# STM32MP23_CM33 register map
File version: 1.2
CPU: CM33 r0p1, little endian, MPU, FPU, vendor SysTick, 8 interrupt priority bits
Registers are 32-bit, read-write, reset 0x0 unless marked. A register's access mark holds for its fields unless they carry their own. Offsets are from the block's base; [hi:lo] are bit positions; {n}, {i} and the like mark numbered series; 'fields as' and 'values as' point back to an identical list.

## TIM16 — General purpose timers
Base 0x40260000
Same registers: TIM17 0x40270000, TIM16_S 0x50260000, TIM17_S 0x50270000
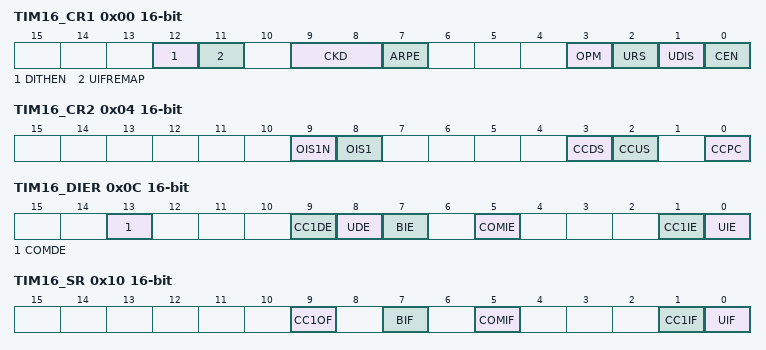
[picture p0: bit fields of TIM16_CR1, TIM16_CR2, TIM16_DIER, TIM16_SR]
0x00 TIM16_CR1 16-bit — TIM16 control register 1
  [12] DITHEN — Dithering enable Note: The DITHEN bit can only be modified when CEN bit is reset.
    0=Dithering disabled; 1=Dithering enabled
  [11] UIFREMAP — UIF status bit remapping
    0=No remapping. UIF status bit is not copied to TIMx_CNT register bit 31.; 1=Remapping enabled. UIF status bit is copied to TIMx_CNT register bit 31.
  [9:8] CKD — Clock division This bit-field indicates the division ratio between the timer clock (tim_ker_ck) frequency and the dead-time and sampling clock (tDTS)used by the dead-time generators and the digital filters (tim_tix),
    0=tDTS=ttim_ker_ck; 1=tDTS=2*ttim_ker_ck; 2=tDTS=4*ttim_ker_ck
  [7] ARPE — Auto-reload preload enable
    0=TIMx_ARR register is not buffered; 1=TIMx_ARR register is buffered
  [3] OPM — One pulse mode
    0=Counter is not stopped at update event; 1=Counter stops counting at the next update event (clearing the bit CEN)
  [2] URS — Update request source This bit is set and cleared by software to select the UEV event sources. Counter overflow/underflow Setting the UG bit Update generation through the slave mode controller
    0=Any of the following events generate an update interrupt or DMA request if enabled. These events can be:; 1=nly counter overflow/underflow generates an update interrupt or DMA request if enabled
  [1] UDIS — Update disable This bit is set and cleared by software to enable/disable UEV event generation. Counter overflow/underflow Setting the UG bit Update generation through the slave mode controller Buffered registers are then loaded with their preload values.
    0=UEV enabled. The Update (UEV) event is generated by one of the following events:; 1=UEV disabled. The Update event is not generated, shadow registers keep their value (ARR, PSC, CCRx). However the counter and the prescaler are reinitialized if the UG bit is set or if a hardware reset is received from the slave mode controller.
  [0] CEN — Counter enable Note: External clock and gated mode can work only if the CEN bit has been previously set by software. However trigger mode can set the CEN bit automatically by hardware.
    0=Counter disabled; 1=Counter enabled
0x04 TIM16_CR2 16-bit — TIM16 control register 2
  [9] OIS1N — Output Idle state 1 (tim_oc1n output) Note: This bit can not be modified as long as LOCK level 1, 2 or 3 has been programmed (LOCK bits in TIMx_BKR register).
    0=tim_oc1n=0 after a dead-time when MOE=0; 1=tim_oc1n=1 after a dead-time when MOE=0
  [8] OIS1 — Output Idle state 1 (tim_oc1 output) Note: This bit can not be modified as long as LOCK level 1, 2 or 3 has been programmed (LOCK bits in TIMx_BKR register).
    0=tim_oc1=0 after a dead-time when MOE=0; 1=tim_oc1=1 after a dead-time when MOE=0
  [3] CCDS — Capture/compare DMA selection
    0=CCx DMA request sent when CCx event occurs; 1=CCx DMA requests sent when update event occurs
  [2] CCUS — Capture/compare control update selection Note: This bit acts only on channels that have a complementary output.
    0=When capture/compare control bits are preloaded (CCPC=1), they are updated by setting the COMG bit only; 1=When capture/compare control bits are preloaded (CCPC=1), they are updated by setting the COMG bit or when a rising edge occurs on tim_trgi (if available)
  [0] CCPC — Capture/compare preloaded control Note: This bit acts only on channels that have a complementary output.
    0=CCxE, CCxNE and OCxM bits are not preloaded; 1=CCxE, CCxNE and OCxM bits are preloaded, after having been written, they are updated only when COM bit is set
0x0C TIM16_DIER 16-bit — TIM16 DMA/interrupt enable register
  [13] COMDE — COM DMA request enable
    0=COM DMA request disabled; 1=COM DMA request enabled
  [9] CC1DE — Capture/Compare 1 DMA request enable
    0=CC1 DMA request disabled; 1=CC1 DMA request enabled
  [8] UDE — Update DMA request enable
    0=Update DMA request disabled; 1=Update DMA request enabled
  [7] BIE — Break interrupt enable
    0=Break interrupt disabled; 1=Break interrupt enabled
  [5] COMIE — COM interrupt enable
    0=COM interrupt disabled; 1=COM interrupt enabled
  [1] CC1IE — Capture/Compare 1 interrupt enable
    0=CC1 interrupt disabled; 1=CC1 interrupt enabled
  [0] UIE — Update interrupt enable
    0=Update interrupt disabled; 1=Update interrupt enabled
0x10 TIM16_SR 16-bit — TIM16 status register
  [9] CC1OF — Capture/Compare 1 overcapture flag This flag is set by hardware only when the corresponding channel is configured in input capture mode. It is cleared by software by writing it to 0 .
    0=No overcapture has been detected; 1=The counter value has been captured in TIMx_CCR1 register while CC1IF flag was already set
  [7] BIF — Break interrupt flag This flag is set by hardware as soon as the tim_brk input goes active. It can be cleared by software if the break input is not active.
    0=No break event occurred; 1=An active level has been detected on the break input
  [5] COMIF — COM interrupt flag This flag is set by hardware on a COM event (once the capture/compare control bits CCxE, CCxNE, OCxM  have been updated). It is cleared by software.
    0=No COM event occurred; 1=COM interrupt pending
  [1] CC1IF — Capture/Compare 1 interrupt flag This flag is set by hardware. It is cleared by software (input capture or output compare mode) or by reading the TIMx_CCR1 register (input capture mode only). If channel CC1 is configured as output: this flag is set when the content of the counter TIMx_CNT matches the content of the TIMx_CCR1 register. When the content of TIMx_CCR1 is greater than the content of TIMx_ARR, the CC1IF bit goes high on the counter overflow (in up-counting and up/down-counting modes) or underflow (in down-counting mode). There are 3 possible options for flag setting in center-aligned mode, refer to the CMS bits in the TIMx_CR1 register for the full description. If channel CC1 is configured as input: this bit is set when counter value has been captured in TIMx_CCR1 register (an edge has been detected on IC1, as per the edge sensitivity defined with the CC1P and CC1NP bits setting, in TIMx_CCER).
    0=No compare match / No input capture occurred; 1=A compare match or an input capture occurred
  [0] UIF — Update interrupt flag This bit is set by hardware on an update event. It is cleared by software. At overflow regarding the repetition counter value (update if repetition counter = 0) and if the UDIS=0 in the TIMx_CR1 register. When CNT is reinitialized by software using the UG bit in TIMx_EGR register, if URS=0 and UDIS=0 in the TIMx_CR1 register.
    0=No update occurred; 1=Update interrupt pending. This bit is set by hardware when the registers are updated:
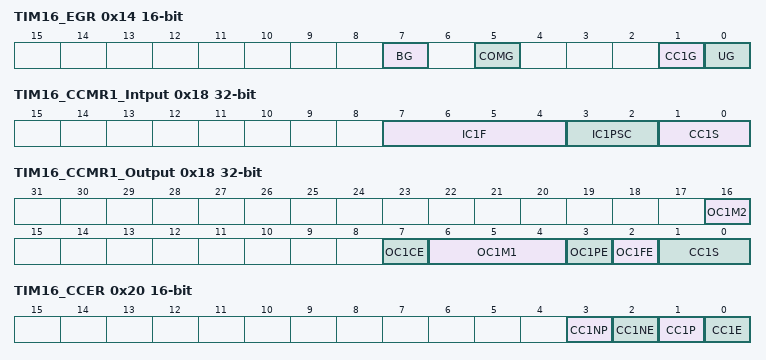
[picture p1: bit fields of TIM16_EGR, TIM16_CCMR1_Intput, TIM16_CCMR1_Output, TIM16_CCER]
0x14 TIM16_EGR 16-bit wo — TIM16 event generation register
  [7] BG — Break generation This bit is set by software in order to generate an event, it is automatically cleared by hardware.
    0=No action; 1=A break event is generated. MOE bit is cleared and BIF flag is set. Related interrupt or DMA transfer can occur if enabled.
  [5] COMG — Capture/Compare control update generation This bit can be set by software, it is automatically cleared by hardware. Note: This bit acts only on channels that have a complementary output.
    0=No action; 1=When the CCPC bit is set, it is possible to update the CCxE, CCxNE and OCxM bits
  [1] CC1G — Capture/Compare 1 generation This bit is set by software in order to generate an event, it is automatically cleared by hardware. If channel CC1 is configured as output: CC1IF flag is set, Corresponding interrupt or DMA request is sent if enabled. If channel CC1 is configured as input: The current value of the counter is captured in TIMx_CCR1 register. The CC1IF flag is set, the corresponding interrupt or DMA request is sent if enabled. The CC1OF flag is set if the CC1IF flag was already high.
    0=No action; 1=A capture/compare event is generated on channel 1:
  [0] UG — Update generation This bit can be set by software, it is automatically cleared by hardware.
    0=No action; 1=Reinitialize the counter and generates an update of the registers. Note that the prescaler counter is cleared too (anyway the prescaler ratio is not affected).
0x18 TIM16_CCMR1_Intput — TIM16 capture/compare mode register 1 [alternate]
  [7:4] IC1F — Input capture 1 filter This bit-field defines the frequency used to sample tim_ti1 input and the length of the digital filter applied to tim_ti1. The digital filter is made of an event counter in which N consecutive events are needed to validate a transition on the output:
    0=No filter, sampling is done at fDTS; 1=fSAMPLING=ftim_ker_ck, N=2; 2=fSAMPLING=ftim_ker_ck, N=4; 3=fSAMPLING=ftim_ker_ck, N=8; 4=fSAMPLING=fDTS/2, N=; 5=fSAMPLING=fDTS/2, N=8; 6=fSAMPLING=fDTS/4, N=6; 7=fSAMPLING=fDTS/4, N=8; 8=fSAMPLING=fDTS/8, N=6; 9=fSAMPLING=fDTS/8, N=8; 10=fSAMPLING=fDTS/16, N=5; 11=fSAMPLING=fDTS/16, N=6; 12=fSAMPLING=fDTS/16, N=8; 13=fSAMPLING=fDTS/32, N=5; 14=fSAMPLING=fDTS/32, N=6; 15=fSAMPLING=fDTS/32, N=8
  [3:2] IC1PSC — Input capture 1 prescaler This bit-field defines the ratio of the prescaler acting on CC1 input (tim_ic1). The prescaler is reset as soon as CC1E= 0 (TIMx_CCER register).
    0=no prescaler, capture is done each time an edge is detected on the capture input; 1=capture is done once every 2 events; 2=capture is done once every 4 events; 3=capture is done once every 8 events
  [1:0] CC1S — Capture/Compare 1 selection This bit-field defines the direction of the channel (input/output) as well as the used input. Others: Reserved Note: CC1S bits are writable only when the channel is OFF (CC1E = 0 in TIMx_CCER).
    0=CC1 channel is configured as output; 1=CC1 channel is configured as input, tim_ic1 is mapped on tim_ti1
0x18 TIM16_CCMR1_Output (alternate view of TIM16_CCMR1_Intput) — TIM16 capture/compare mode register 1 [alternate]
  [16] OC1M2 — Output Compare 1 mode These bits define the behavior of the output reference signal tim_oc1ref from which tim_oc1 and tim_oc1n are derived. tim_oc1ref is active high whereas tim_oc1 and tim_oc1n active level depends on CC1P and CC1NP bits. Others: Reserved Note: These bits can not be modified as long as LOCK level 3 has been programmed (LOCK bits in TIMx_BDTR register) and CC1S= 00 (the channel is configured in output). In PWM mode 1 or 2, the tim_oc1ref level changes only when the result of the comparison changes or when the output compare mode switches from frozen  mode to PWM  mode.
    0=Frozen - The comparison between the output compare register TIMx_CCR1 and the counter TIMx_CNT has no effect on the outputs; 1=Set channel 1 to active level on match. tim_oc1ref signal is forced high when the counter TIMx_CNT matches the capture/compare register 1 (TIMx_CCR1).
  [7] OC1CE — Output Compare 1 clear enable
    0=tim_oc1ref is not affected by the tim_ocref_clr input; 1=tim_oc1ref is cleared as soon as a High level is detected on tim_ocref_clr input
  [6:4] OC1M1 — Output Compare 1 mode These bits define the behavior of the output reference signal tim_oc1ref from which tim_oc1 and tim_oc1n are derived. tim_oc1ref is active high whereas tim_oc1 and tim_oc1n active level depends on CC1P and CC1NP bits. Others: Reserved Note: These bits can not be modified as long as LOCK level 3 has been programmed (LOCK bits in TIMx_BDTR register) and CC1S= 00 (the channel is configured in output). In PWM mode 1 or 2, the tim_oc1ref level changes only when the result of the comparison changes or when the output compare mode switches from frozen  mode to PWM  mode.
    0=Frozen - The comparison between the output compare register TIMx_CCR1 and the counter TIMx_CNT has no effect on the outputs; 1=Set channel 1 to active level on match. tim_oc1ref signal is forced high when the counter TIMx_CNT matches the capture/compare register 1 (TIMx_CCR1).; 2=Set channel 1 to inactive level on match. tim_oc1ref signal is forced low when the counter TIMx_CNT matches the capture/compare register 1 (TIMx_CCR1).; 3=Toggle - tim_oc1ref toggles when TIMx_CNT=TIMx_CCR1; 4=Force inactive level - tim_oc1ref is forced low; 5=Force active level - tim_oc1ref is forced high; 6=PWM mode 1 - Channel 1 is active as long as TIMx_CNTTIMx_CCR1 else inactive; 7=PWM mode 2 - Channel 1 is inactive as long as TIMx_CNTTIMx_CCR1 else active
  [3] OC1PE — Output Compare 1 preload enable Note: These bits can not be modified as long as LOCK level 3 has been programmed (LOCK bits in TIMx_BDTR register) and CC1S= 00 (the channel is configured in output). The PWM mode can be used without validating the preload register only in one pulse mode (OPM bit set in TIMx_CR1 register). Else the behavior is not guaranteed.
    0=Preload register on TIMx_CCR1 disabled. TIMx_CCR1 can be written at anytime, the new value is taken in account immediately.; 1=Preload register on TIMx_CCR1 enabled. Read/Write operations access the preload register. TIMx_CCR1 preload value is loaded in the active register at each update event.
  [2] OC1FE — Output Compare 1 fast enable This bit decreases the latency between a trigger event and a transition on the timer output. It must be used in one-pulse mode (OPM bit set in TIMx_CR1 register), to have the output pulse starting as soon as possible after the starting trigger.
    0=CC1 behaves normally depending on counter and CCR1 values even when the trigger is ON. The minimum delay to activate CC1 output when an edge occurs on the trigger input is 5 clock cycles.; 1=An active edge on the trigger input acts like a compare match on CC1 output. Then, tim_ocx is set to the compare level independently of the result of the comparison. Delay to sample the trigger input and to activate CC1 output is reduced to 3 clock cycles. OC1FE acts only if the channel is configured in PWM1 or PWM2 mode.
  [1:0] CC1S — Capture/Compare 1 selection This bit-field defines the direction of the channel (input/output) as well as the used input. Others: Reserved Note: CC1S bits are writable only when the channel is OFF (CC1E = 0 in TIMx_CCER).
    values as TIM16_CCMR1_Intput.CC1S
0x20 TIM16_CCER 16-bit — TIM16 capture/compare enable register
  [3] CC1NP — Capture/Compare 1 complementary output polarity CC1 channel configured as output: CC1 channel configured as input: This bit is used in conjunction with CC1P to define the polarity of tim_ti1fp1. Refer to the description of CC1P. Note: This bit is not writable as soon as LOCK level 2 or 3 has been programmed (LOCK bits in TIMx_BDTR register) and CC1S= 00  (the channel is configured in output). On channels that have a complementary output, this bit is preloaded. If the CCPC bit is set in the TIMx_CR2 register then the CC1NP active bit takes the new value from the preloaded bit only when a commutation event is generated.
    0=tim_oc1n active high; 1=tim_oc1n active low
  [2] CC1NE — Capture/Compare 1 complementary output enable
    0=Off - tim_oc1n is not active. tim_oc1n level is then function of MOE, OSSI, OSSR, OIS1, OIS1N and CC1E bits.; 1=On - tim_oc1n signal is output on the corresponding output pin depending on MOE, OSSI, OSSR, OIS1, OIS1N and CC1E bits
  [1] CC1P — Capture/Compare 1 output polarity When CC1 channel is configured as input, both CC1NP/CC1P bits select the active polarity of TI1FP1 and TI2FP1 for trigger or capture operations. CC1NP=0, CC1P=0: non-inverted/rising edge. The circuit is sensitive to TIxFP1 rising edge (capture or trigger operations in reset, external clock or trigger mode), TIxFP1 is not inverted (trigger operation in gated mode or encoder mode). CC1NP=0, CC1P=1: inverted/falling edge. The circuit is sensitive to TIxFP1 falling edge (capture or trigger operations in reset, external clock or trigger mode), TIxFP1 is inverted (trigger operation in gated mode or encoder mode). CC1NP=1, CC1P=1: non-inverted/both edges/ The circuit is sensitive to both TIxFP1 rising and falling edges (capture or trigger operations in reset, external clock or trigger mode), TIxFP1is not inverted (trigger operation in gated mode). This configuration must not be used in encoder mode. CC1NP=1, CC1P=0: this configuration is reserved, it must not be used. Note: This bit is not writable as soon as LOCK level 2 or 3 has been programmed (LOCK bits in TIMx_BDTR register). On channels that have a complementary output, this bit is preloaded. If the CCPC bit is set in the TIMx_CR2 register then the CC1P active bit takes the new value from the preloaded bit only when a Commutation event is generated.
    0=OC1 active high (output mode) / Edge sensitivity selection (input mode, see below); 1=OC1 active low (output mode) / Edge sensitivity selection (input mode, see below)
  [0] CC1E — Capture/Compare 1 output enable When CC1 channel is configured as output, the OC1 level depends on MOE, OSSI, OSSR, OIS1, OIS1N and CC1NE bits, regardless of the CC1E bits state. Refer to for details.
    0=Capture mode disabled / OC1 is not active (see below); 1=Capture mode enabled / OC1 signal is output on the corresponding output pin
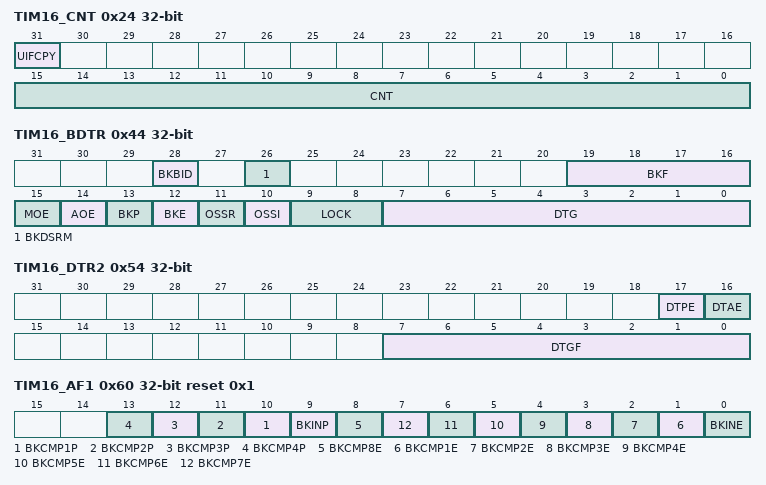
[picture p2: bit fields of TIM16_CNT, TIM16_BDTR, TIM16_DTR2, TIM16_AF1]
0x24 TIM16_CNT access per field — TIM16 counter
  [31] UIFCPY ro — UIF Copy This bit is a read-only copy of the UIF bit of the TIMx_ISR register. If the UIFREMAP bit in TIMx_CR1 is reset, bit 31 is reserved.
  [15:0] CNT rw — Counter value Non-dithering mode (DITHEN = 0) The register holds the counter value. Dithering mode (DITHEN = 1) The register only holds the non-dithered part in CNT[15:0]. The fractional part is not available.
0x28 TIM16_PSC 16-bit — TIM16 prescaler
  [15:0] PSC — Prescaler value The counter clock frequency (tim_cnt_ck) is equal to ftim_psc_ck / (PSC[15:0] + 1). PSC contains the value to be loaded in the active prescaler register at each update event (including when the counter is cleared through UG bit of TIMx_EGR register or through trigger controller when configured in reset mode ).
0x2C TIM16_ARR reset 0xFFFF — TIM16 auto-reload register
  [19:0] ARR — Auto-reload value ARR is the value to be loaded in the actual auto-reload register. Refer to the for more details about ARR update and behavior. The counter is blocked while the auto-reload value is null. Non-dithering mode (DITHEN = 0) The register holds the auto-reload value in ARR[15:0]. The ARR[19:16] bits are reset. Dithering mode (DITHEN = 1) The register holds the integer part in ARR[19:4]. The ARR[3:0] bitfield contains the dithered part.
0x30 TIM16_RCR 16-bit — TIM16 repetition counter register
  [7:0] REP — Repetition counter reload value This bitfield defines the update rate of the compare registers (i.e. periodic transfers from preload to active registers) when preload registers are enable. It also defines the update interrupt generation rate, if this interrupt is enable. When the repetition down-counter reaches zero, an update event is generated and it restarts counting from REP value. As the repetition counter is reloaded with REP value only at the repetition update event UEV, any write to the TIMx_RCR register is not taken in account until the next repetition update event. It means in PWM mode (REP+1) corresponds to the number of PWM periods in edge-aligned mode: the number of PWM periods in edge-aligned mode the number of half PWM period in center-aligned mode
0x34 TIM16_CCR1 — TIM16 capture/compare register 1
  [19:0] CCR1 — Capture/Compare 1 value If channel CC1 is configured as output: CCR1 is the value to be loaded in the actual capture/compare 1 register (preload value). It is loaded permanently if the preload feature is not selected in the TIMx_CCMR1 register (bit OC1PE). Else the preload value is copied in the active capture/compare 1 register when an update event occurs. The active capture/compare register contains the value to be compared to the counter TIMx_CNT and signaled on tim_oc1 output. Non-dithering mode (DITHEN = 0) The register holds the compare value in CCR1[15:0]. The CCR1[19:16] bits are reset. Dithering mode (DITHEN = 1) The register holds the integer part in CCR1[19:4]. The CCR1[3:0] bitfield contains the dithered part. If channel CC1 is configured as input: CCR1 is the counter value transferred by the last input capture 1 event (tim_ic1). Non-dithering mode (DITHEN = 0) The register holds the capture value in CCR1[15:0]. The CCR1[19:16] bits are reset. Dithering mode (DITHEN = 1) The register holds the capture in CCR1[19:4]. The CCR1[3:0] bits are reset.
0x44 TIM16_BDTR — TIM16 break and dead-time register
  [28] BKBID — Break Bidirectional In the bidirectional mode (BKBID bit set to 1), the break input is configured both in input mode and in open drain output mode. Any active break event asserts a low logic level on the Break input to indicate an internal break event to external devices. Note: This bit cannot be modified as long as LOCK level 1 has been programmed (LOCK bits in TIMx_BDTR register). Note: Any write operation to this bit takes a delay of 1 APB clock cycle to become effective.
    0=Break input tim_brk in input mode; 1=Break input tim_brk in bidirectional mode
  [26] BKDSRM — Break Disarm This bit is cleared by hardware when no break source is active. The BKDSRM bit must be set by software to release the bidirectional output control (open-drain output in Hi-Z state) and then be polled it until it is reset by hardware, indicating that the fault condition has disappeared. Note: Any write operation to this bit takes a delay of 1 APB clock cycle to become effective.
    0=Break input tim_brk is armed; 1=Break input tim_brk is disarmed
  [19:16] BKF — Break filter This bit-field defines the frequency used to sample tim_brk input and the length of the digital filter applied to tim_brk. The digital filter is made of an event counter in which N events are needed to validate a transition on the output: This bit cannot be modified when LOCK level 1 has been programmed (LOCK bits in TIMx_BDTR register).
    0=No filter, tim_brk acts asynchronously; 1=fSAMPLING=ftim_ker_ck, N=2; 2=fSAMPLING=ftim_ker_ck, N=4; 3=fSAMPLING=ftim_ker_ck, N=8; 4=fSAMPLING=fDTS/2, N=6; 5=fSAMPLING=fDTS/2, N=8; 6=fSAMPLING=fDTS/4, N=6; 7=fSAMPLING=fDTS/4, N=8; 8=fSAMPLING=fDTS/8, N=6; 9=fSAMPLING=fDTS/8, N=8; 10=fSAMPLING=fDTS/16, N=5; 11=fSAMPLING=fDTS/16, N=6; 12=fSAMPLING=fDTS/16, N=8; 13=fSAMPLING=fDTS/32, N=5; 14=fSAMPLING=fDTS/32, N=6; 15=fSAMPLING=fDTS/32, N=8
  [15] MOE — Main output enable This bit is cleared asynchronously by hardware as soon as the tim_brk input is active. It is set by software or automatically depending on the AOE bit. It is acting only on the channels which are configured in output. See tim_oc1/tim_oc1n enable description for more details (capture/compare enable register (TIMx_CCER)(x = 16 to 17) on page 1457).
    0=tim_oc1 and tim_oc1n outputs are disabled or forced to idle state depending on the OSSI bit; 1=tim_oc1 and tim_oc1n outputs are enabled if their respective enable bits are set (CC1E, CC1NE in TIMx_CCER register)
  [14] AOE — Automatic output enable Note: This bit can not be modified as long as LOCK level 1 has been programmed (LOCK bits in TIMx_BDTR register).
    0=MOE can be set only by software; 1=MOE can be set by software or automatically at the next update event (if the tim_brk input is not active)
  [13] BKP — Break polarity Note: This bit can not be modified as long as LOCK level 1 has been programmed (LOCK bits in TIMx_BDTR register). Any write operation to this bit takes a delay of 1 APB clock cycle to become effective.
    0=Break input tim_brk is active low; 1=Break input tim_brk is active high
  [12] BKE — Break enable 1; Break inputs (tim_brk and tim_sys_brk event) enabled Note: This bit cannot be modified when LOCK level 1 has been programmed (LOCK bits in TIMx_BDTR register). Any write operation to this bit takes a delay of 1 APB clock cycle to become effective.
    0=Break inputs (tim_brk and tim_sys_brk event) disabled
  [11] OSSR — Off-state selection for Run mode This bit is used when MOE=1 on channels that have a complementary output which are configured as outputs. OSSR is not implemented if no complementary output is implemented in the timer. See tim_oc1/tim_oc1n enable description for more details (capture/compare enable register (TIMx_CCER)(x = 16 to 17) on page 1457). Note: This bit can not be modified as soon as the LOCK level 2 has been programmed (LOCK bits in TIMx_BDTR register).
    0=When inactive, tim_oc1/tim_oc1n outputs are disabled (the timer releases the output control which is taken over by the GPIO, which forces a Hi-Z state); 1=When inactive, tim_oc1/tim_oc1n outputs are enabled with their inactive level as soon as CC1E=1 or CC1NE=1 (the output is still controlled by the timer)
  [10] OSSI — Off-state selection for Idle mode This bit is used when MOE=0 on channels configured as outputs. See tim_oc1/tim_oc1n enable description for more details (capture/compare enable register (TIMx_CCER)(x = 16 to 17) on page 1457). Note: This bit can not be modified as soon as the LOCK level 2 has been programmed (LOCK bits in TIMx_BDTR register).
    0=When inactive, tim_oc1/tim_oc1n outputs are disabled (tim_oc1/tim_oc1n enable output signal=0); 1=When inactive, tim_oc1/tim_oc1n outputs are forced first with their idle level as soon as CC1E=1 or CC1NE=1. tim_oc1/tim_oc1n enable output signal=1)
  [9:8] LOCK — Lock configuration These bits offer a write protection against software errors. Note: The LOCK bits can be written only once after the reset. Once the TIMx_BDTR register has been written, their content is frozen until the next reset.
    0=LOCK OFF - No bit is write protected; 1=LOCK Level 1 = DTG bits in TIMx_BDTR register, OISx and OISxN bits in TIMx_CR2 register and BKBID/BKE/BKP/AOE bits in TIMx_BDTR register can no longer be written; 2=LOCK Level 2 = LOCK Level 1 + CC Polarity bits (CCxP/CCxNP bits in TIMx_CCER register, as long as the related channel is configured in output through the CCxS bits) as well as OSSR and OSSI bits can no longer be written; 3=LOCK Level 3 = LOCK Level 2 + CC Control bits (OCxM and OCxPE bits in TIMx_CCMRx registers, as long as the related channel is configured in output through the CCxS bits) can no longer be written
  [7:0] DTG — Dead-time generator setup This bit-field defines the duration of the dead-time inserted between the complementary outputs. DT correspond to this duration. DTG[7:5]=0xx = DT=DTG[7:0]x tdtg with tdtg=tDTS DTG[7:5]=10x = DT=(64+DTG[5:0])xtdtg with Tdtg=2xtDTS DTG[7:5]=110 = DT=(32+DTG[4:0])xtdtg with Tdtg=8xtDTS DTG[7:5]=111 = DT=(32+DTG[4:0])xtdtg with Tdtg=16xtDTS Example if TDTS=125ns (8MHz), dead-time possible values are: 0 to 15875 ns by 125 ns steps, 16 us to 31750 ns by 250 ns steps, 32 us to 63 us by 1 us steps, 64 us to 126 us by 2 us steps Note: This bit-field can not be modified as long as LOCK level 1, 2 or 3 has been programmed (LOCK bits in TIMx_BDTR register).
0x54 TIM16_DTR2 — TIM16 timer deadtime register 2
  [17] DTPE — Deadtime preload enable Note: This bit can not be modified as long as LOCK level 1, 2 or 3 has been programmed (LOCK bits in TIMx_BDTR register).
    0=Deadtime value is not preloaded; 1=Deadtime value preload is enabled
  [16] DTAE — Deadtime asymmetric enable Note: This bit can not be modified as long as LOCK level 1, 2 or 3 has been programmed (LOCK bits in TIMx_BDTR register).
    0=Deadtime on rising and falling edges are identical, and defined with DTG[7:0] register; 1=Deadtime on rising edge is defined with DTG[7:0] register and deadtime on falling edge is defined with DTGF[7:0] bits
  [7:0] DTGF — Dead-time falling edge generator setup This bit-field defines the duration of the dead-time inserted between the complementary outputs, on the falling edge. DTGF[7:5]=0xx = DTF=DTGF[7:0]x tdtg with tdtg=tDTS. DTGF[7:5]=10x = DTF=(64+DTGF[5:0])xtdtg with Tdtg=2xtDTS. DTGF[7:5]=110 = DTF=(32+DTGF[4:0])xtdtg with Tdtg=8xtDTS. DTGF[7:5]=111 = DTF=(32+DTGF[4:0])xtdtg with Tdtg=16xtDTS. Example if TDTS=125ns (8MHz), dead-time possible values are: 0 to 15875 ns by 125 ns steps, 16 us to 31750 ns by 250 ns steps, 32 us to 63us by 1 us steps, 64 us to 126 us by 2 us steps Note: This bit-field can not be modified as long as LOCK level 1, 2 or 3 has been programmed (LOCK bits in TIMx_BDTR register).
0x5C TIM16_TISEL — TIM16 input selection register
  [3:0] TI1SEL — selects tim_ti1_in[0..15] input ... Refer to for interconnects list.
    0=TIMx_CH1 input (tim_ti1_in0); 1=tim_ti1_in1; 15=tim_ti1_in15
0x60 TIM16_AF1 reset 0x1 — TIM16 alternate function register 1
  [n+9] BKCMP{n}P (n=1..4) — tim_brk_cmp{n} input polarity This bit selects the tim_brk_cmp{n} input sensitivity. It must be programmed together with the BKP polarity bit. Note: This bit can not be modified as long as LOCK level 1 has been programmed (LOCK bits in TIMx_BDTR register).
    0=tim_brk_cmp{n} input is active high; 1=tim_brk_cmp{n} input is active low
  [9] BKINP — TIMx_BKIN input polarity This bit selects the TIMx_BKIN alternate function input sensitivity. It must be programmed together with the BKP polarity bit. Note: This bit can not be modified as long as LOCK level 1 has been programmed (LOCK bits in TIMx_BDTR register).
    0=TIMx_BKIN input is active high; 1=TIMx_BKIN input is active low
  [8] BKCMP8E — tim_brk_cmp8 enable This bit enables the tim_brk_cmp8 for the timer s tim_brk input. mdf_brkx output is ORed with the other tim_brk sources. Note: This bit can not be modified as long as LOCK level 1 has been programmed (LOCK bits in TIMx_BDTR register).
    0=tim_brk_cmp8 input disabled; 1=tim_brk_cmp8 input enabled
  [n] BKCMP{n}E (n=1..7) — tim_brk_cmp{n} enable This bit enables the tim_brk_cmp{n} for the timer s tim_brk input. tim_brk_cmp{n} output is ORed with the other tim_brk sources. Note: This bit can not be modified as long as LOCK level 1 has been programmed (LOCK bits in TIMx_BDTR register).
    0=tim_brk_cmp{n} input disabled; 1=tim_brk_cmp{n} input enabled
  [0] BKINE — TIMx_BKIN input enable This bit enables the TIMx_BKIN alternate function input for the timer s tim_brk input. TIMx_BKIN input is ORed with the other tim_brk sources. Note: This bit can not be modified as long as LOCK level 1 has been programmed (LOCK bits in TIMx_BDTR register).
    0=TIMx_BKIN input disabled; 1=TIMx_BKIN input enabled
0x64 TIM16_AF2 — TIM16 alternate function register 2
  [18:16] OCRSEL — tim_ocref_clr source selection These bits select the tim_ocref_clr input source. Refer to for product specific implementation. Note: These bits can not be modified as long as LOCK level 1 has been programmed (LOCK bits in TIMx_BDTR register).
    {v}=tim_ocref_clr{v} (v=0..7)
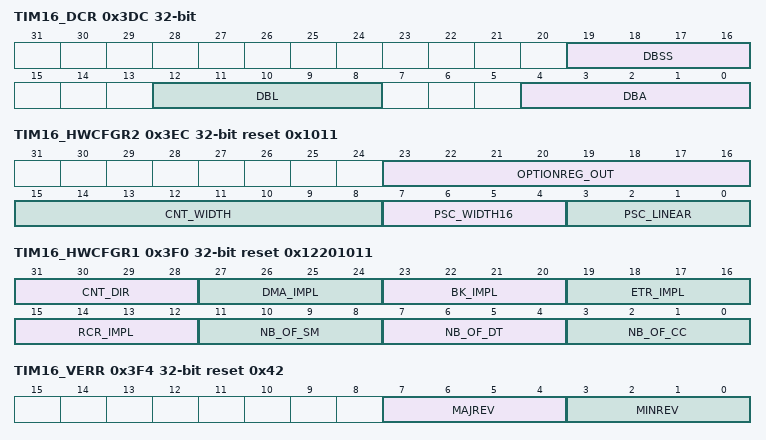
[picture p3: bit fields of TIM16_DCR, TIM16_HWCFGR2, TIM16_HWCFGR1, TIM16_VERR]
0x3DC TIM16_DCR — TIM16 DMA control register
  [19:16] DBSS — DMA burst source selection This bitfield defines the interrupt source that triggers the DMA burst transfers (the timer recognizes a burst transfer when a read or a write access is done to the TIMx_DMAR address). Other: reserved
    1=Update; {v}=CC{v-1} (v=2..5); 6=COM; 7=Trigger
  [12:8] DBL — DMA burst length This 5-bit field defines the length of DMA transfers (the timer recognizes a burst transfer when a read or a write access is done to the TIMx_DMAR address), i.e. the number of transfers. Transfers can be in half-words or in bytes (see example below). ...
    0=1 transfer,; 1=2 transfers,; 2=3 transfers,; 17=18 transfers
  [4:0] DBA — DMA base address This 5-bit field defines the base-address for DMA transfers (when read/write access are done through the TIMx_DMAR address). DBA is defined as an offset starting from the address of the TIMx_CR1 register. Example: ... Example: Let us consider the following transfer: DBL = 7 transfers and DBA = TIMx_CR1. In this case the transfer is done to/from 7 registers starting from the TIMx_CR1 address.
    0=TIMx_CR1,; 1=TIMx_CR2,; 2=TIMx_SMCR,
0x3E0 TIM16_DMAR — TIM16/TIM17 DMA address for full transfer
  [31:0] DMAB — DMA register for burst accesses A read or write operation to the DMAR register accesses the register located at the address (TIMx_CR1 address) + (DBA + DMA index) x 4 where TIMx_CR1 address is the address of the control register 1, DBA is the DMA base address configured in TIMx_DCR register, DMA index is automatically controlled by the DMA transfer, and ranges from 0 to DBL (DBL configured in TIMx_DCR).
0x3EC TIM16_HWCFGR2 ro reset 0x1011 — TIM16 hardware configuration 2 register
  [23:16] OPTIONREG_OUT — Option register number (0 to 16).
  [15:8] CNT_WIDTH — Counter width Others: Reserved
    8=8-bits; 16=16-bits; 32=32-bits
  [7:4] PSC_WIDTH16 — Prescaler width Others: Reserved
    0=7 (by power of 2) /8 (linear) -bit counter; 1=15 (by power of 2) /16 (linear) -bit counter
  [3:0] PSC_LINEAR — Prescaler linear Others: Reserved
    0=prescaler by power of 2 (division by 1, 2, 4, 8...); 1=prescaler is linear (division by 1, 2, 3, 4, 5...)
0x3F0 TIM16_HWCFGR1 ro reset 0x12201011 — TIM16 hardware configuration 1 register
  [31:28] CNT_DIR — Counter direction Others: Reserved
    0=Down-counter only; 1=Up-counter only; 2=Up/Down counter allowing center-aligned mode
  [27:24] DMA_IMPL — DMA features implementation Others: Reserved
    0=DMA requests are not possible; 1=Single DMA requests possible; 2=All DMA features implemented
  [23:20] BK_IMPL — Break circuit implementation Others: Reserved
    0=no break implemented; 1=break1 implemented without filter (tim_brk + tim_sys_brk connected); 2=break1 implemented with filter (tim_brk + tim_sys_brk connected); 3=break 1 and 2 implemented (tim_brk + tim_sys_brk + brk2)
  [19:16] ETR_IMPL — External trigger implementation Others: Reserved
    0=External trigger circuit not implemented, ocrefx cleared by ocref_clr input; 1=External trigger circuit implemented, ocrefx cleared by ocref_clr input; 2=External trigger circuit implemented, ocrefx cleared by etrf signal; 3=External trigger circuit implemented, ocrefx cleared by ocref_clr or etrf (1 control bit OCCS  added in GPT_SMCR)
  [15:12] RCR_IMPL — Repetition counter implementation Others: Reserved
    0=repetition counter not implemented; 1=8-bit repetition counter implemented; 2=16-bit repetition counter implemented
  [11:8] NB_OF_SM — Number of synchronization module Others: Reserved
    0=synchronization module not implemented; 1=1 synchronization module implemented
  [7:4] NB_OF_DT — Number of complementary outputs and dead-time generators 0x0 0x1 0x2 0x3 0x4 Others: Reserved
  [3:0] NB_OF_CC — Number of capture / compare channel Others: Reserved
    0=no capture/compare channel implemented; 1=only CC1 channel is implemented; 2=CC1 and CC2 channels are implemented; 3=CC1, CC2 and CC3 channels are implemented; 4=CC1, CC2, CC3 and CC4 channels are implemented; 5=CC1, CC2, CC3, CC4 and CC5 channels are implemented; 6=CC1, CC2, CC3, CC4, CC5 and CC6 channels are implemented
0x3F4 TIM16_VERR ro reset 0x42 — TIM16 IP version register
  [7:4] MAJREV — Major revision number. 0x4
  [3:0] MINREV — Minor revision number. 0x2
0x3F8 TIM16_IPIDR ro reset 0x120002 — TIM16 IP identification register
  [31:0] ID — IP identification code. 0x00120002
0x3FC TIM16_SIDR ro reset 0xA3C5DD01 — TIM16 size ID register
  [31:0] SID — Fixed code. 0xA3C5DD nullOffset in KB of the ID register base address from the IP base address.
    1=1KB offset
